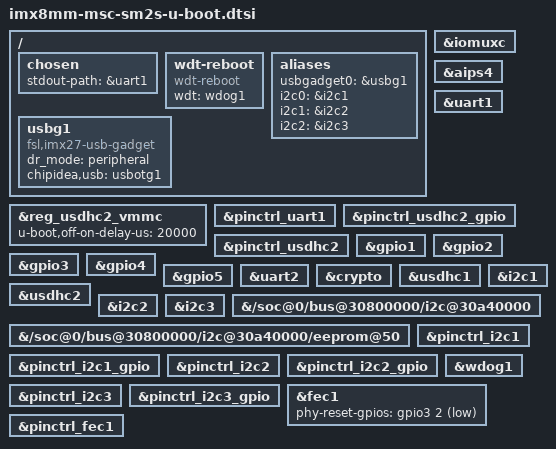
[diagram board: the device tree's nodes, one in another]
// SPDX-License-Identifier: GPL-2.0+
/*
 * Copyright 2024 Avnet Silica
 */

#include "imx8mm-u-boot.dtsi"

/ {
	chosen {
		stdout-path = &uart1;
	};

	wdt-reboot {
		compatible = "wdt-reboot";
		wdt = <&wdog1>;
		u-boot,dm-spl;
	};

	aliases {
		usbgadget0 = &usbg1;
		i2c0 = &i2c1;
		i2c1 = &i2c2;
		i2c2 = &i2c3;
	};

	usbg1: usbg1 {
		compatible = "fsl,imx27-usb-gadget";
		dr_mode = "peripheral";
		chipidea,usb = <&usbotg1>;
		status = "okay";
	};
};

&iomuxc {
	u-boot,dm-spl;
};

&aips4 {
	u-boot,dm-spl;
};

&reg_usdhc2_vmmc {
	u-boot,off-on-delay-us = <20000>;
	u-boot,dm-spl;
};

&pinctrl_uart1 {
	u-boot,dm-spl;
};

&uart1 {
	u-boot,dm-spl;
};

&pinctrl_usdhc2_gpio {
	u-boot,dm-spl;
};

&pinctrl_usdhc2 {
	u-boot,dm-spl;
};

&gpio1 {
	u-boot,dm-spl;
};

&gpio2 {
	u-boot,dm-spl;
};

&gpio3 {
	u-boot,dm-spl;
};

&gpio4 {
	u-boot,dm-spl;
};

&gpio5 {
	u-boot,dm-spl;
};

&uart2 {
	u-boot,dm-spl;
};

&crypto {
	u-boot,dm-spl;
};

&usdhc1 {
	u-boot,dm-spl;
};

&usdhc2 {
	u-boot,dm-spl;
};

&i2c1 {
	u-boot,dm-spl;
};

&i2c2 {
	u-boot,dm-spl;
};

&i2c3 {
	u-boot,dm-spl;
};

&{/soc@0/bus@30800000/i2c@30a40000} {
	u-boot,dm-spl;
};

&{/soc@0/bus@30800000/i2c@30a40000/eeprom@50} {
	u-boot,dm-spl;
};

&pinctrl_i2c1 {
	u-boot,dm-spl;
};

&pinctrl_i2c1_gpio {
	u-boot,dm-spl;
};

&pinctrl_i2c2 {
	u-boot,dm-spl;
};

&pinctrl_i2c2_gpio {
	u-boot,dm-spl;
};

&pinctrl_i2c3 {
	u-boot,dm-spl;
};

&pinctrl_i2c3_gpio {
	u-boot,dm-spl;
};

&wdog1 {
	u-boot,dm-spl;
};

&fec1 {
	phy-reset-gpios = <&gpio3 2 GPIO_ACTIVE_LOW>;
	u-boot,dm-spl;
};

&pinctrl_fec1 {
	u-boot,dm-spl;
};
